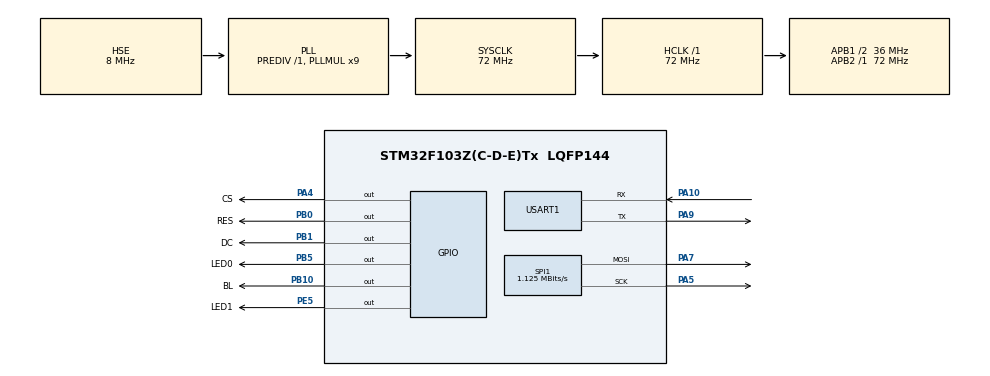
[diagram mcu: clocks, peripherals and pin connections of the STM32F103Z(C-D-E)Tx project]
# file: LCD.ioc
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FREERTOS.Tasks01=defaultTask,24,128,StartDefaultTask,Default,NULL,Dynamic,NULL,NULL
Mcu.Family=STM32F1
Mcu.Name=STM32F103Z(C-D-E)Tx
Mcu.Package=LQFP144
NVIC.PriorityGroup=NVIC_PRIORITYGROUP_4
NVIC.TIM8_UP_IRQn=true\:15\:0\:false\:false\:true\:false\:false\:true\:true
NVIC.TimeBase=TIM8_UP_IRQn
NVIC.TimeBaseIP=TIM8
OSC_IN.Mode=HSE-External-Oscillator
OSC_IN.Signal=RCC_OSC_IN
OSC_OUT.Mode=HSE-External-Oscillator
OSC_OUT.Signal=RCC_OSC_OUT
PA10.Mode=Asynchronous
PA10.Signal=USART1_RX
PA13.Mode=Serial_Wire
PA13.Signal=SYS_JTMS-SWDIO
PA14.Mode=Serial_Wire
PA14.Signal=SYS_JTCK-SWCLK
PA4.GPIO_Label=CS
PA4.Signal=GPIO_Output
PA5.Mode=TX_Only_Simplex_Unidirect_Master
PA5.Signal=SPI1_SCK
PA7.Mode=TX_Only_Simplex_Unidirect_Master
PA7.Signal=SPI1_MOSI
PA9.Mode=Asynchronous
PA9.Signal=USART1_TX
PB0.GPIO_Label=RES
PB0.Signal=GPIO_Output
PB1.GPIO_Label=DC
PB1.Signal=GPIO_Output
PB10.GPIO_Label=BL
PB10.Signal=GPIO_Output
PB5.GPIO_Label=LED0
PB5.Signal=GPIO_Output
PE5.GPIO_Label=LED1
PE5.Signal=GPIO_Output
ProjectManager.HeapSize=0x200
ProjectManager.StackSize=0x400
ProjectManager.TargetToolchain=MDK-ARM V5.32
RCC.AHBFreq_Value=72000000
RCC.APB1CLKDivider=RCC_HCLK_DIV2
RCC.APB1Freq_Value=36000000
RCC.APB1TimFreq_Value=72000000
RCC.APB2Freq_Value=72000000
RCC.APB2TimFreq_Value=72000000
RCC.HCLKFreq_Value=72000000
RCC.PLLMUL=RCC_PLL_MUL9
RCC.PLLSourceVirtual=RCC_PLLSOURCE_HSE
RCC.SYSCLKFreq_VALUE=72000000
RCC.SYSCLKSource=RCC_SYSCLKSOURCE_PLLCLK
RCC.USBFreq_Value=72000000
SPI1.BaudRatePrescaler=SPI_BAUDRATEPRESCALER_64
SPI1.CLKPhase=SPI_PHASE_2EDGE
SPI1.CLKPolarity=SPI_POLARITY_HIGH
SPI1.CalculateBaudRate=1.125 MBits/s
SPI1.Direction=SPI_DIRECTION_2LINES
SPI1.Mode=SPI_MODE_MASTER
SPI1.VirtualType=VM_MASTER
USART1.VirtualMode=VM_ASYNC
VP_FREERTOS_VS_CMSIS_V2.Mode=CMSIS_V2
VP_SYS_VS_tim8.Mode=TIM8
board=custom

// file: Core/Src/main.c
/* USER CODE BEGIN Header */
/**
  ******************************************************************************
  * @file           : main.c
  * @brief          : Main program body
  ******************************************************************************
  * @attention
  *
  * Copyright (c) 2026 STMicroelectronics.
  * All rights reserved.
  *
  * This software is licensed under terms that can be found in the LICENSE file
  * in the root directory of this software component.
  * If no LICENSE file comes with this software, it is provided AS-IS.
  *
  ******************************************************************************
  */
/* USER CODE END Header */
#include "main.h"
#include "cmsis_os.h"

/* Definitions for defaultTask */
osThreadId_t defaultTaskHandle;
const osThreadAttr_t defaultTask_attributes = {
  .name = "defaultTask",
  .stack_size = 128 * 4,
  .priority = (osPriority_t) osPriorityNormal,
};

void SystemClock_Config(void);

void StartDefaultTask(void *argument);

int main(void)
{

  /* MCU Configuration--------------------------------------------------------*/

  /* Reset of all peripherals, Initializes the Flash interface and the Systick. */
  HAL_Init();

  /* Configure the system clock */
  SystemClock_Config();

  /* Initialize all configured peripherals */
  MX_GPIO_Init();
  MX_SPI1_Init();
  MX_USART1_UART_Init();

  /* Init scheduler */
  osKernelInitialize();

  /* Create the thread(s) */
  /* creation of defaultTask */
  defaultTaskHandle = osThreadNew(StartDefaultTask, NULL, &defaultTask_attributes);

  /* Start scheduler */
  osKernelStart();

  /* We should never get here as control is now taken by the scheduler */
  /* Infinite loop */
  while (1)
  {

  }
}

void SystemClock_Config(void)
{
  RCC_OscInitTypeDef RCC_OscInitStruct = {0};
  RCC_ClkInitTypeDef RCC_ClkInitStruct = {0};

  /** Initializes the RCC Oscillators according to the specified parameters
  * in the RCC_OscInitTypeDef structure.
  */
  RCC_OscInitStruct.OscillatorType = RCC_OSCILLATORTYPE_HSE;
  RCC_OscInitStruct.HSEState = RCC_HSE_ON;
  RCC_OscInitStruct.HSEPredivValue = RCC_HSE_PREDIV_DIV1;
  RCC_OscInitStruct.HSIState = RCC_HSI_ON;
  RCC_OscInitStruct.PLL.PLLState = RCC_PLL_ON;
  RCC_OscInitStruct.PLL.PLLSource = RCC_PLLSOURCE_HSE;
  RCC_OscInitStruct.PLL.PLLMUL = RCC_PLL_MUL9;
  if (HAL_RCC_OscConfig(&RCC_OscInitStruct) != HAL_OK)
  {
    Error_Handler();
  }

  /** Initializes the CPU, AHB and APB buses clocks
  */
  RCC_ClkInitStruct.ClockType = RCC_CLOCKTYPE_HCLK|RCC_CLOCKTYPE_SYSCLK
                              |RCC_CLOCKTYPE_PCLK1|RCC_CLOCKTYPE_PCLK2;
  RCC_ClkInitStruct.SYSCLKSource = RCC_SYSCLKSOURCE_PLLCLK;
  RCC_ClkInitStruct.AHBCLKDivider = RCC_SYSCLK_DIV1;
  RCC_ClkInitStruct.APB1CLKDivider = RCC_HCLK_DIV2;
  RCC_ClkInitStruct.APB2CLKDivider = RCC_HCLK_DIV1;

  if (HAL_RCC_ClockConfig(&RCC_ClkInitStruct, FLASH_LATENCY_2) != HAL_OK)
  {
    Error_Handler();
  }
}

void StartDefaultTask(void *argument)
{
  /* USER CODE BEGIN 5 */
  /* Infinite loop */
  for(;;)
  {
    osDelay(1);
	  HAL_Delay(300);
    HAL_GPIO_TogglePin(LED1_GPIO_Port, LED1_Pin);
  }
  /* USER CODE END 5 */
}

void HAL_TIM_PeriodElapsedCallback(TIM_HandleTypeDef *htim)
{
  if (htim->Instance == TIM8) {
    HAL_IncTick();
  }
}

void Error_Handler(void)
{
  __disable_irq();
  while (1)
  {
  }
}
